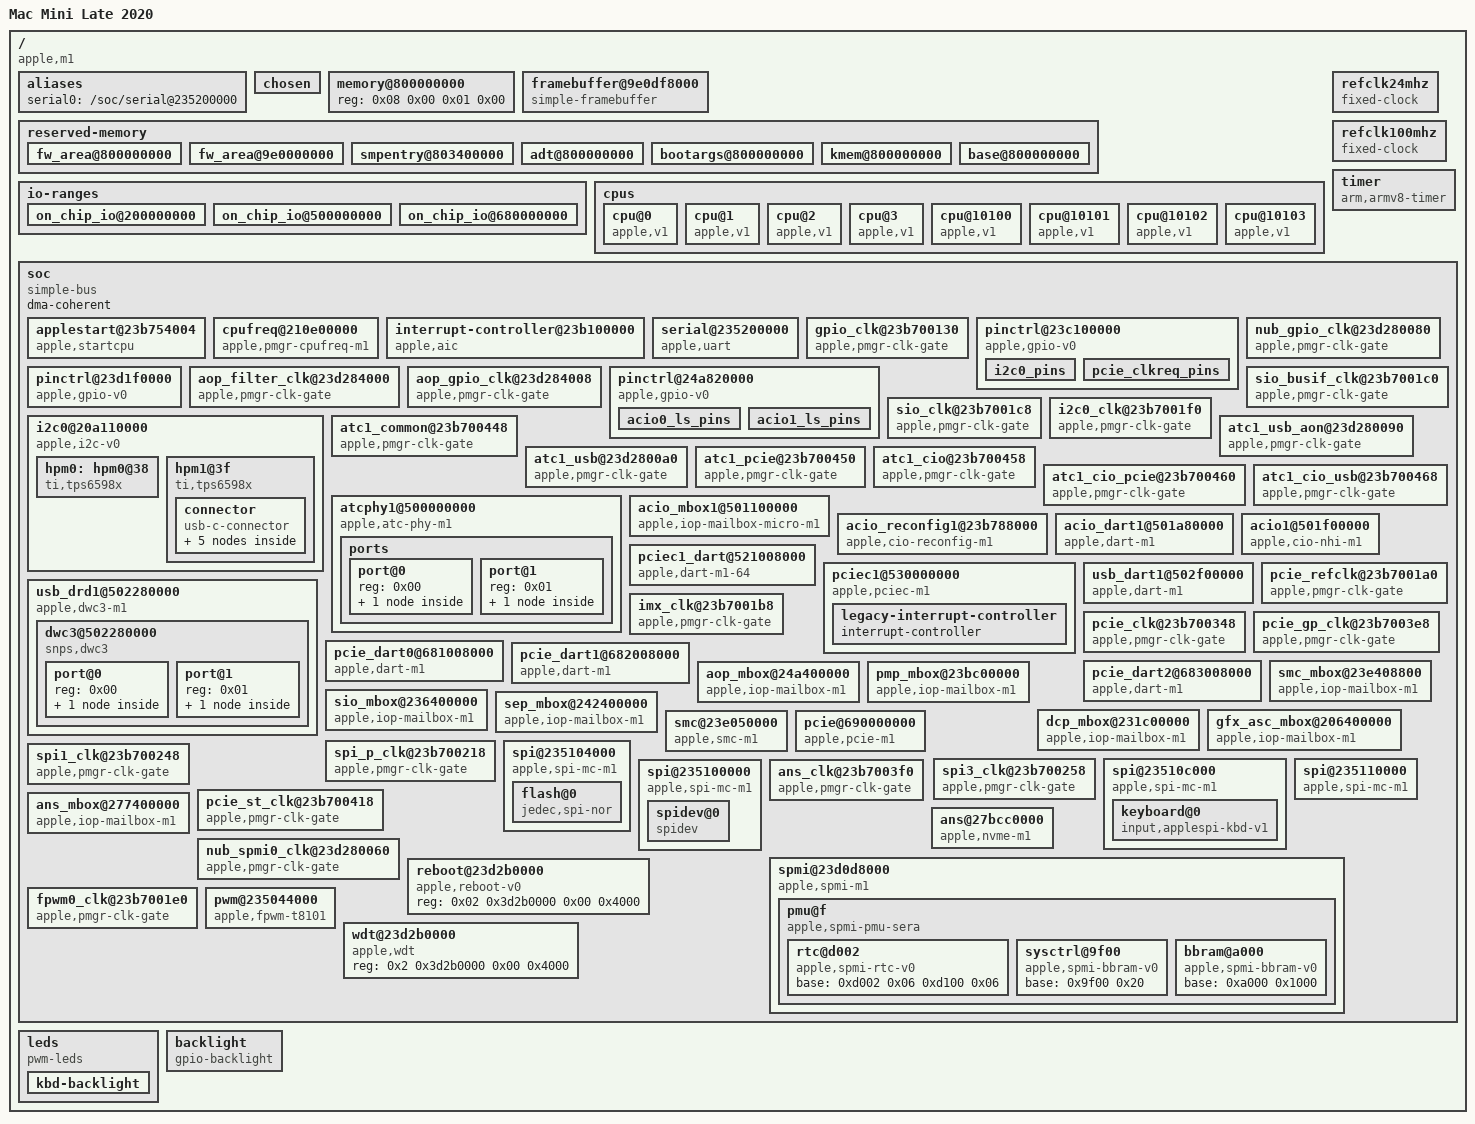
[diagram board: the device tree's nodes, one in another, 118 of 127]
/dts-v1/;

/ {
	model = "Mac Mini Late 2020";
	compatible = "apple,m1";
	hardware-model = "J274";
	interrupt-parent = <0x01>;
	#address-cells = <0x02>;
	#size-cells = <0x02>;

	aliases {
		serial0 = "/soc/serial@235200000";
	};

	chosen {
		bootargs = "earlycon=apple_uart,0x235200000 console=tty0";
	};

	memory@800000000 {
		device_type = "memory";
		reg = <0x08 0x00 0x01 0x00>;
	};

	framebuffer@9e0df8000 {
		compatible = "simple-framebuffer";
		reg = <0x0b 0xdf438000 0x00 0x3e80000>;
		format = "x8r8g8b8";
		height = <0x640>;
		stride = <0x2800>;
		width = <0xa00>;
		status = "okay";
		backlight = <0x02>;
	};

	reserved-memory {
		#address-cells = <0x02>;
		#size-cells = <0x02>;
		ranges;

		fw_area@800000000 {
			reg = <0x08 0x00 0x00 0x1f44000>;
			no-map;
		};

		fw_area@9e0000000 {
			reg = <0x0b 0xd9498000 0x00 0x26b68000>;
			no-map;
		};

		smpentry@803400000 {
			reg = <0x08 0x4df4000 0x00 0x4000>;
			no-map;
		};

		adt@800000000 {
			reg = "adtgoeshere!!!!";
			no-map;
		};

		bootargs@800000000 {
			reg = "bootargsgohere!";
			no-map;
		};

		kmem@800000000 {
			reg = "kmemgoeshere!!!";
			no-map;
		};

		base@800000000 {
			reg = "basegoeshere!!!";
			no-map;
		};
	};

	io-ranges {
		#address-cells = <0x02>;
		#size-cells = <0x02>;
		ranges;

		on_chip_io@200000000 {
			reg = <0x02 0x00 0x02 0x00>;
			type = <0x01>;
		};

		on_chip_io@500000000 {
			reg = <0x05 0x00 0x00 0x80000000>;
			type = <0x01>;
		};

		on_chip_io@680000000 {
			reg = <0x06 0x80000000 0x00 0x20000000>;
			type = <0x01>;
		};
	};

	cpus {
		#address-cells = <0x01>;
		#size-cells = <0x00>;

		cpu@0 {
			device_type = "cpu";
			compatible = "apple,v1";
			reg = <0x00>;
			enable-method = "apple,startcpu";
			apple,cluster = <0x00>;
		};

		cpu@1 {
			device_type = "cpu";
			compatible = "apple,v1";
			reg = <0x01>;
			enable-method = "apple,startcpu";
			apple,cluster = <0x00>;
		};

		cpu@2 {
			device_type = "cpu";
			compatible = "apple,v1";
			reg = <0x02>;
			enable-method = "apple,startcpu";
			apple,cluster = <0x00>;
		};

		cpu@3 {
			device_type = "cpu";
			compatible = "apple,v1";
			reg = <0x03>;
			enable-method = "apple,startcpu";
			apple,cluster = <0x00>;
		};

		cpu@10100 {
			device_type = "cpu";
			compatible = "apple,v1";
			reg = <0x10100>;
			enable-method = "apple,startcpu";
			apple,cluster = <0x01>;
		};

		cpu@10101 {
			device_type = "cpu";
			compatible = "apple,v1";
			reg = <0x10101>;
			enable-method = "apple,startcpu";
			apple,cluster = <0x01>;
		};

		cpu@10102 {
			device_type = "cpu";
			compatible = "apple,v1";
			reg = <0x10102>;
			enable-method = "apple,startcpu";
			apple,cluster = <0x01>;
		};

		cpu@10103 {
			device_type = "cpu";
			compatible = "apple,v1";
			reg = <0x10103>;
			enable-method = "apple,startcpu";
			apple,cluster = <0x01>;
		};
	};

	refclk24mhz {
		compatible = "fixed-clock";
		#clock-cells = <0x00>;
		clock-frequency = <0x16e3600>;
		clock-output-names = "refclk24mhz";
		phandle = <0x03>;
	};

	refclk100mhz {
		compatible = "fixed-clock";
		#clock-cells = <0x00>;
		clock-frequency = <0x5f5e100>;
		clock-output-names = "refclk100mhz";
		phandle = <0x17>;
	};

	timer {
		compatible = "arm,armv8-timer";
		interrupts = <1 1 4 1 0 4>;
		clock-frequency = <0x16e3600>;
	};

	soc {
		compatible = "simple-bus";
		#address-cells = <0x02>;
		#size-cells = <0x02>;
		ranges;
		dma-coherent;

		applestart@23b754004 {
			compatible = "apple,startcpu";
			reg = <0x02 0x3b754004 0x00 0x0c 0x02 0x10050000 0x00 0x08 0x02 0x10030fb0 0x00 0x04 0x02 0x3b754004 0x00 0x0c 0x02 0x10150000 0x00 0x08 0x02 0x10130fb0 0x00 0x04 0x02 0x3b754004 0x00 0x0c 0x02 0x10250000 0x00 0x08 0x02 0x10230fb0 0x00 0x04 0x02 0x3b754004 0x00 0x0c 0x02 0x10350000 0x00 0x08 0x02 0x10330fb0 0x00 0x04 0x02 0x3b754004 0x00 0x0c 0x02 0x11050000 0x00 0x08 0x02 0x11030fb0 0x00 0x04 0x02 0x3b754004 0x00 0x0c 0x02 0x11150000 0x00 0x08 0x02 0x11130fb0 0x00 0x04 0x02 0x3b754004 0x00 0x0c 0x02 0x11250000 0x00 0x08 0x02 0x11230fb0 0x00 0x04 0x02 0x3b754004 0x00 0x0c 0x02 0x11350000 0x00 0x08 0x02 0x11330fb0 0x00 0x04>;
		};

		cpufreq@210e00000 {
			compatible = "apple,pmgr-cpufreq-m1";
			reg = <0x02 0x10e00000 0x00 0x100000 0x02 0x11e00000 0x00 0x100000 0x02 0x3b700000 0x00 0x100000 0x02 0x200000 0x00 0x200000>;
			tunable-ecpu-states = <0x1aaaa 0x22c 0x1075f 0x26d 0xc031 0x2a6 0x963c 0x300 0x7c07 0x35b>;
			tunable-pcpu-states = <0x1aaaa 0x254 0x1352d 0x27d 0xf26c 0x2a3 0xc760 0x2a9 0xaaaa 0x2d1 0x9425 0x2e4 0x82e1 0x310 0x7537 0x320 0x6b33 0x342 0x62c3 0x377 0x5c5a 0x3a0 0x55ad 0x3d2 0x52af 0x3d2 0x516c 0x3d2 0x4fe6 0x3d2>;
			tunable-pcpu-fast-freq = <0x888>;
			tunable-pcpu-fast-dcfg = <0x133 0x55555340>;
		};

		interrupt-controller@23b100000 {
			compatible = "apple,aic";
			#interrupt-cells = <0x03>;
			interrupt-controller;
			reg = <0x02 0x3b100000 0x00 0x8000>;
			fast-ipi;
			phandle = <0x01>;
		};

		serial@235200000 {
			compatible = "apple,uart";
			reg = <0x02 0x35200000 0x00 0x4000>;
			interrupts = <0x00 0x25d 0x04>;
			clocks = <0x03>;
			clock-names = "refclk";
			index = <0x00>;
		};

		gpio_clk@23b700130 {
			compatible = "apple,pmgr-clk-gate";
			#clock-cells = <0x00>;
			reg = <0x02 0x3b700130 0x00 0x08>;
			clocks = <0x03>;
			clock-output-names = "gpio_clk";
			phandle = <0x04>;
		};

		pinctrl@23c100000 {
			compatible = "apple,gpio-v0";
			reg = <0x02 0x3c100000 0x00 0x100000>;
			pin-count = <0xd4>;
			interrupts = <0x00 0xbe 0x04 0x00 0xbf 0x04 0x00 0xc0 0x04 0x00 0xc1 0x04 0x00 0xc2 0x04 0x00 0xc3 0x04 0x00 0xc4 0x04>;
			clocks = <0x04>;
			gpio-controller;
			#gpio-cells = <0x02>;
			interrupt-controller;
			#interrupt-cells = <0x02>;
			phandle = <0x0c>;

			i2c0_pins {
				pins = "gpio192\0gpio188";
				function = "periph";
				phandle = <0x0b>;
			};

			pcie_clkreq_pins {
				pins = "gpio150\0gpio151\0gpio32";
				function = "periph";
				phandle = <0x36>;
			};
		};

		nub_gpio_clk@23d280080 {
			compatible = "apple,pmgr-clk-gate";
			#clock-cells = <0x00>;
			reg = <0x02 0x3d280080 0x00 0x08>;
			clocks = <0x03>;
			clock-output-names = "nub_gpio_clk";
			phandle = <0x05>;
		};

		pinctrl@23d1f0000 {
			compatible = "apple,gpio-v0";
			reg = <0x02 0x3d1f0000 0x00 0x4000>;
			pin-count = <0x17>;
			pin-base = <0xd4>;
			pin-prefix = "nubgpio";
			interrupts = <0x00 0x14a 0x04 0x00 0x14b 0x04 0x00 0x14c 0x04 0x00 0x14d 0x04 0x00 0x14e 0x04 0x00 0x14f 0x04 0x00 0x150 0x04>;
			clocks = <0x05>;
			gpio-controller;
			#gpio-cells = <0x02>;
			interrupt-controller;
			#interrupt-cells = <0x02>;
			phandle = <0x3f>;
		};

		aop_filter_clk@23d284000 {
			compatible = "apple,pmgr-clk-gate";
			#clock-cells = <0x00>;
			reg = <0x02 0x3d284000 0x00 0x08>;
			clocks = <0x03>;
			clock-output-names = "aop_filter_clk";
			phandle = <0x06>;
		};

		aop_gpio_clk@23d284008 {
			compatible = "apple,pmgr-clk-gate";
			#clock-cells = <0x00>;
			reg = <0x02 0x3d284008 0x00 0x08>;
			clocks = <0x06>;
			clock-output-names = "aop_gpio_clk";
			phandle = <0x07>;
		};

		pinctrl@24a820000 {
			compatible = "apple,gpio-v0";
			reg = <0x02 0x4a820000 0x00 0x4000>;
			pin-count = <0x2a>;
			pin-base = <0xeb>;
			pin-prefix = "aopgpio";
			interrupts = <0x00 0x10c 0x04 0x00 0x10d 0x04 0x00 0x10e 0x04 0x00 0x10f 0x04 0x00 0x110 0x04 0x00 0x111 0x04 0x00 0x112 0x04>;
			clocks = <0x07>;
			gpio-controller;
			#gpio-cells = <0x02>;
			interrupt-controller;
			#interrupt-cells = <0x02>;

			acio0_ls_pins {
				pins = "aopgpio39";
				function = "periph";
			};

			acio1_ls_pins {
				pins = "aopgpio41";
				function = "periph";
				phandle = <0x28>;
			};
		};

		sio_busif_clk@23b7001c0 {
			compatible = "apple,pmgr-clk-gate";
			#clock-cells = <0x00>;
			reg = <0x02 0x3b7001c0 0x00 0x08>;
			clocks = <0x03>;
			clock-output-names = "sio_busif_clk";
			phandle = <0x08>;
		};

		sio_clk@23b7001c8 {
			compatible = "apple,pmgr-clk-gate";
			#clock-cells = <0x00>;
			reg = <0x02 0x3b7001c8 0x00 0x08>;
			clocks = <0x08>;
			clock-output-names = "sio_clk";
			phandle = <0x09>;
		};

		i2c0_clk@23b7001f0 {
			compatible = "apple,pmgr-clk-gate";
			#clock-cells = <0x00>;
			reg = <0x02 0x3b7001f0 0x00 0x08>;
			clocks = <0x09>;
			clock-output-names = "i2c0_clk";
			phandle = <0x0a>;
		};

		i2c0@20a110000 {
			compatible = "apple,i2c-v0";
			reg = <0x02 0x35010000 0x00 0x4000>;
			interrupts = <0x00 0x273 0x04>;
			clocks = <0x0a>;
			pinctrl-0 = <0x0b>;
			pinctrl-names = "default";
			#address-cells = <0x01>;
			#size-cells = <0x00>;

            hpm0: hpm0@38 {
                compatible = "ti,tps6598x";
                reg = <0x38>;
                interrupt-parent = <0x0c>;
                interrupts = <106 8>;

                no-long-writes;
		just-init;
            };

			hpm1@3f {
				compatible = "ti,tps6598x";
				reg = <0x3f>;
				interrupt-parent = <0x0c>;
				interrupts = <0x6a 0x08>;
				no-long-writes;

				connector {
					compatible = "usb-c-connector";
					label = "USB-C B";
					power-role = "source";
					data-role = "host";

					ports {
						#address-cells = <0x01>;
						#size-cells = <0x00>;

						port@0 {
							reg = <0x00>;

							endpoint {
								remote-endpoint = <0x0d>;
								phandle = <0x2e>;
							};
						};

						port@1 {
							reg = <0x01>;

							endpoint {
								remote-endpoint = <0x0e>;
								phandle = <0x20>;
							};
						};
					};
				};
			};
		};

		atc1_common@23b700448 {
			compatible = "apple,pmgr-clk-gate";
			#clock-cells = <0x00>;
			reg = <0x02 0x3b700448 0x00 0x08>;
			clocks = <0x03>;
			clock-output-names = "atc1_common";
			phandle = <0x1c>;
		};

		atc1_usb_aon@23d280090 {
			compatible = "apple,pmgr-clk-gate";
			#clock-cells = <0x00>;
			reg = <0x02 0x3d280090 0x00 0x08>;
			clocks = <0x1c>;
			clock-output-names = "atc1_usb_aon";
			phandle = <0x1d>;
		};

		atc1_usb@23d2800a0 {
			compatible = "apple,pmgr-clk-gate";
			#clock-cells = <0x00>;
			reg = <0x02 0x3d2800a0 0x00 0x08>;
			clocks = <0x1d>;
			clock-output-names = "atc1_usb";
			phandle = <0x1f>;
		};

		atc1_pcie@23b700450 {
			compatible = "apple,pmgr-clk-gate";
			#clock-cells = <0x00>;
			reg = <0x02 0x3b700450 0x00 0x08>;
			clocks = <0x1c>;
			clock-output-names = "atc1_pcie";
			phandle = <0x2a>;
		};

		atc1_cio@23b700458 {
			compatible = "apple,pmgr-clk-gate";
			#clock-cells = <0x00>;
			reg = <0x02 0x3b700458 0x00 0x08>;
			clocks = <0x1c>;
			clock-output-names = "atc1_cio";
			phandle = <0x1e>;
		};

		atc1_cio_pcie@23b700460 {
			compatible = "apple,pmgr-clk-gate";
			#clock-cells = <0x00>;
			reg = <0x02 0x3b700460 0x00 0x08>;
			clocks = <0x1e>;
			clock-output-names = "atc1_cio_pcie";
			phandle = <0x22>;
		};

		atc1_cio_usb@23b700468 {
			compatible = "apple,pmgr-clk-gate";
			#clock-cells = <0x00>;
			reg = <0x02 0x3b700468 0x00 0x08>;
			clocks = <0x1e>;
			clock-output-names = "atc1_cio_usb";
			phandle = <0x23>;
		};

		atcphy1@500000000 {
			compatible = "apple,atc-phy-m1";
			clocks = <0x1f>;
			reg = <0x05 0x00 0x00 0x1000000 0x05 0x2000000 0x00 0x1080000>;
			#phy-cells = <0x00>;
			usb-role-switch;
			orientation-switch;
			mode-switch;
			accessory;
			#clock-cells = <0x00>;
			clock-output-names = "utmi1clk";
			phandle = <0x27>;
			tunable-ATC0AXI2AF = <0x00 0x03 0x00 0x30 0xffffffff 0xffff 0x34 0xffffffff 0xffff 0x400 0x400103ff 0x40010001 0x600 0x1ffffff 0x1ffffff 0x738 0x1ff01ff 0x400040 0x798 0x1ff01ff 0x600020 0x800 0x100 0x100 0x900 0x03 0x00 0x920 0x03 0x00>;
			tunable-ATC_FABRIC = <0x11045004 0x3f003f 0x200020 0x1104500c 0xf1 0xa1 0x11045010 0x801f 0x04 0x11045018 0x3f003f 0x200020 0x11045020 0xf1 0xa1 0x11045024 0x801f 0x04 0x1104502c 0x7f007f 0x520052 0x11045034 0xf1 0x71 0x11045038 0x01 0x01 0x1104503c 0x01 0x01 0x11045040 0x801f 0x04 0x11045048 0x1f 0x10 0x11045050 0x801f 0x04 0x11045058 0x7f007f 0x450045 0x11045060 0xf1 0x51 0x11045064 0x801f 0x04 0x1104506c 0x3f 0x20 0x11045074 0x801f 0x04 0x1104507c 0x01 0x01 0x11045080 0x801f 0x04 0x11045088 0x1f001f 0x100010 0x11045090 0x01 0x01 0x11045094 0x01 0x01 0x11045098 0x801f 0x04 0x110450a0 0xff00ff 0xc000c0 0x110450a4 0x801f 0x04 0x110450ac 0x3f 0x20 0x110450b4 0x801f 0x04 0x110450bc 0x3f 0x20 0x110450c4 0x801f 0x04 0x110450cc 0x1f001f 0x100010 0x110450d4 0x01 0x01 0x110450d8 0x01 0x01 0x110450dc 0x801f 0x04 0x110450e4 0x01 0x01 0x110450e8 0x01 0x01 0x110450ec 0x801f 0x04 0x110450f4 0xffffffff 0x1010101 0x110450f8 0xffff 0x101 0x110450fc 0xffffffff 0x1010101 0x11045100 0xffff 0x101 0x11045104 0x801f 0x04 0x1104510c 0x01 0x01 0x11045110 0x01 0x01 0x11045114 0x801f 0x04 0x1104511c 0x01 0x01 0x11045120 0x01 0x01 0x11045124 0x801f 0x04 0x1104512c 0x01 0x01 0x11045130 0x01 0x01 0x11045134 0x801f 0x04 0x1104513c 0x01 0x01 0x11045140 0x801f 0x04 0x11045148 0x01 0x01 0x1104514c 0x01 0x01 0x11045150 0x801f 0x04 0x11045158 0x801f 0x04 0x11045160 0xffffffff 0x1010101 0x11045164 0xffffffff 0x1010101 0x11045168 0xffff 0x101 0x1104516c 0x801f 0x04 0x11045174 0x01 0x01 0x11045178 0x01 0x01 0x1104517c 0x801f 0x04 0x11045184 0x01 0x01 0x11045188 0x801f 0x04 0x1104508c 0xf1 0x11>;
			tunable-AUS_CMN_SHM = <0x11000a00 0x3fc00 0x3c000>;
			tunable-AUS_CMN_TOP = <0x11000808 0xfff0ff0 0x2220220>;
			tunable-AUSPLL_CORE = <0x1100222c 0x900 0x900 0x11002278 0x8000000 0x00 0x110022a4 0x01 0x01>;
			tunable-AUSPLL_TOP = <0x11002088 0xf0000 0x60000 0x11002094 0xf0000 0x60000 0x110020a0 0xf0000 0x50000 0x110020ac 0xf0000 0x50000 0x110020b8 0xf0000 0x50000>;
			tunable-CIO3PLL_CORE = <0x11002a00 0x22 0x22 0x11002a1c 0x7000 0x2000 0x11002a20 0x20007 0x20003 0x11002a28 0x10 0x10 0x11002a9c 0x20000 0x00>;
			tunable-CIO3PLL_TOP = <0x11002810 0xffffffff 0xa0a0a04 0x11002888 0x1ff 0x127 0x11002894 0x1ff 0x115>;
			tunable-CIO_LN0_AUSPMA_RX_EQ = <0x1100a048 0x0f 0x02 0x1100a050 0xfff 0xfff 0x1100a054 0x0f 0x02 0x1100a05c 0xfff 0xfff 0x1100a07c 0xfff 0x7ff 0x1100a098 0x3f 0x3f 0x1100a0bc 0x7fc00000 0x3000000 0x1100a048 0x0f 0x02 0x1100a050 0xfff 0xfff 0x1100a054 0x0f 0x02 0x1100a05c 0xfff 0xfff 0x1100a07c 0xfff 0x7ff 0x1100a098 0x3f 0x3f 0x1100a0bc 0x7fc00000 0x3000000>;
			tunable-USB_LN0_AUSPMA_RX_EQ;
			tunable-CIO_LN0_AUSPMA_RX_SHM = <0x1100b01c 0x7fc0fff 0x1c00c21 0x1100b024 0xc000 0xc000 0x1100b028 0x600 0x600 0x1100b02c 0x70 0x50 0x1100b038 0x1f800000 0x13000000 0x1100b03c 0x7000000 0x7000000 0x1100b05c 0x400 0x400 0x1100b084 0x7c1f 0x6815 0x1100b08c 0x1c0000 0x100000 0x1100b01c 0x7fc0fff 0x1c00c21 0x1100b024 0xc000 0xc000 0x1100b028 0x600 0x600 0x1100b02c 0x70 0x50 0x1100b038 0x1f800000 0x13000000 0x1100b03c 0x7000000 0x7000000 0x1100b05c 0x400 0x400 0x1100b084 0xf83e0 0xd02a0 0x1100b08c 0x1c0000 0x100000>;
			tunable-USB_LN0_AUSPMA_RX_SHM = <0x1100b01c 0x7fc0fff 0x1c00c21 0x1100b024 0xc000 0xc000 0x1100b028 0x600 0x600 0x1100b02c 0x70 0x50 0x1100b038 0x1f800008 0x13000008 0x1100b03c 0x7000000 0x7000000 0x1100b080 0xffffffff 0x808550 0x1100b084 0x3f07c1f 0x200701c 0x1100b088 0x3f03f03f 0x20020020 0x1100b08c 0xfc0 0x800 0x1100b01c 0x7fc0fff 0x1c00c21 0x1100b024 0xc000 0xc000 0x1100b028 0x600 0x600 0x1100b02c 0x70 0x50 0x1100b038 0x1f800008 0x13000008 0x1100b03c 0x7000000 0x7000000 0x1100b080 0xffffffff 0x808550 0x1100b084 0x3ff83e0 0x20e0380 0x1100b088 0x3f03f03f 0x20020020 0x1100b08c 0xfc0 0x800>;
			tunable-CIO_LN0_AUSPMA_RX_TOP = <0x11009000 0x7e000000 0x1e000000 0x11009014 0x8000 0x00 0x1100902c 0x4ff6ff3f 0x4aa0ff3f 0x11009030 0x11fff00c 0x11000004 0x11009040 0x30000 0x00 0x11009068 0x38 0x18 0x11009074 0x3f 0x3e 0x11009084 0x1fff0e 0x400a 0x11009088 0x3fff 0x1224 0x110090ac 0x1f8000 0x40000 0x110090ec 0xfffffffc 0x80000 0x11009104 0xffff 0x202 0x11009108 0x03 0x00 0x11009110 0xffffff0 0x2222220 0x11009118 0x02 0x00 0x11009000 0x7e000000 0x1e000000 0x11009014 0x8000 0x00 0x1100902c 0x4ff6ff3f 0x4aa0ff3f 0x11009030 0x11fff00c 0x11000004 0x11009040 0x30000 0x00 0x11009068 0x38 0x18 0x11009074 0x3f 0x3e 0x11009084 0x1fff0e 0x400a 0x11009088 0x3fff 0x1224 0x110090ac 0x1f8000 0x40000 0x110090e4 0xfffffff 0x1a50694 0x110090ec 0xfffffffc 0x80000 0x11009104 0xffff 0x202 0x11009108 0x03 0x00 0x11009110 0xffffff0 0x2222220 0x11009118 0x02 0x00>;
			tunable-USB_LN0_AUSPMA_RX_TOP = <0x11009000 0x7e000000 0x3e000000 0x11009014 0x8000 0x00 0x1100902c 0x20f00f0f 0x20a00f0f 0x11009030 0xff3100 0xff0000 0x11009040 0x30000 0x00 0x11009044 0x30000 0x30000 0x11009068 0x38 0x18 0x11009074 0x3f 0x3e 0x11009084 0x1fff0e 0x400a 0x11009088 0x3fff 0x1224 0x110090ac 0x1f8000 0x40000 0x110090dc 0xffffffff 0xcc28c48a 0x110090ec 0xfffffffc 0x2604 0x110090f4 0xffffffff 0x3280650 0x110090fc 0x7c1f 0x1004 0x11009104 0xffff 0x202 0x11009108 0x03 0x00 0x11009110 0xffffff0 0x2222220 0x11009000 0x7e000000 0x3e000000 0x11009014 0x8000 0x00 0x1100902c 0x20f00f0f 0x20a00f0f 0x11009030 0xff3100 0x00 0x11009040 0x30000 0x00 0x11009044 0x30000 0x30000 0x11009068 0x38 0x18 0x11009074 0x3f 0x3e 0x11009084 0x1fff0e 0x400a 0x11009088 0x3fff 0x1224 0x110090ac 0x1f8000 0x40000 0x110090dc 0xffffffff 0xcc28c48a 0x110090ec 0xfffffffc 0x2604 0x110090f4 0xffffffff 0x3280650 0x110090fc 0x7c1f 0x1004 0x11009104 0xffff 0x202 0x11009108 0x03 0x00 0x11009110 0xffffff0 0x2222220>;
			tunable-CIO_LN0_AUSPMA_TX_TOP = <0x1100c008 0xfc00 0x6c00 0x1100c030 0x3fc0 0x2a00 0x1100c080 0xf80000 0x180000 0x1100c08c 0xffffff0 0x2222220 0x1100c008 0xfc00 0x6c00 0x1100c030 0x3fc0 0x2a00 0x1100c080 0xf80000 0x180000 0x1100c08c 0xffffff0 0x2222220>;
			tunable-DP_LN0_AUSPMA_TX_TOP = <0x1100c008 0xfc00 0x6c00 0x1100c030 0x3fc0 0x2a00 0x1100c08c 0xffffff0 0x2222220 0x1100c080 0xf80000 0x180000>;
			tunable-USB_LN0_AUSPMA_TX_TOP = <0x1100c008 0xfc00 0x6c00 0x1100c018 0x1fffffc0 0x3018180 0x1100c01c 0x7ff 0x5a0 0x1100c030 0x3fc0 0x2a00 0x1100c080 0xf80000 0x180000 0x1100c08c 0xffffff0 0x2222220 0x1100c008 0xfc00 0x6c00 0x1100c018 0x1fffffc0 0x3018180 0x1100c01c 0x7ff 0x5a0 0x1100c030 0x3fc0 0x2a00 0x1100c080 0xf80000 0x180000 0x1100c08c 0xffffff0 0x2222220>;
			tunable-CIO_LN1_AUSPMA_RX_EQ = <0x11011048 0x0f 0x02 0x11011050 0xfff 0xfff 0x11011054 0x0f 0x02 0x1101105c 0xfff 0xfff 0x1101107c 0xfff 0x7ff 0x11011098 0x3f 0x3f 0x110110bc 0x7fc00000 0x3000000 0x11011048 0x0f 0x02 0x11011050 0xfff 0xfff 0x11011054 0x0f 0x02 0x1101105c 0xfff 0xfff 0x1101107c 0xfff 0x7ff 0x11011098 0x3f 0x3f 0x110110bc 0x7fc00000 0x3000000>;
			tunable-USB_LN1_AUSPMA_RX_EQ;
			tunable-CIO_LN1_AUSPMA_RX_SHM = <0x1101201c 0x7fc0fff 0x1c00c21 0x11012024 0xc000 0xc000 0x11012028 0x600 0x600 0x1101202c 0x70 0x50 0x11012038 0x1f800000 0x13000000 0x1101203c 0x7000000 0x7000000 0x1101205c 0x400 0x400 0x11012084 0x7c1f 0x6815 0x1101208c 0x1c0000 0x100000 0x1101201c 0x7fc0fff 0x1c00c21 0x11012024 0xc000 0xc000 0x11012028 0x600 0x600 0x1101202c 0x70 0x50 0x11012038 0x1f800000 0x13000000 0x1101203c 0x7000000 0x7000000 0x1101205c 0x400 0x400 0x11012084 0xf83e0 0xd02a0 0x1101208c 0x1c0000 0x100000>;
			tunable-USB_LN1_AUSPMA_RX_SHM = <0x1101201c 0x7fc0fff 0x1c00c21 0x11012024 0xc000 0xc000 0x11012028 0x600 0x600 0x1101202c 0x70 0x50 0x11012038 0x1f800008 0x13000008 0x1101203c 0x7000000 0x7000000 0x11012080 0xffffffff 0x808550 0x11012084 0x3f07c1f 0x200701c 0x11012088 0x3f03f03f 0x20020020 0x1101208c 0xfc0 0x800 0x1101201c 0x7fc0fff 0x1c00c21 0x11012024 0xc000 0xc000 0x11012028 0x600 0x600 0x1101202c 0x70 0x50 0x11012038 0x1f800008 0x13000008 0x1101203c 0x7000000 0x7000000 0x11012080 0xffffffff 0x808550 0x11012084 0x3ff83e0 0x20e0380 0x11012088 0x3f03f03f 0x20020020 0x1101208c 0xfc0 0x800>;
			tunable-CIO_LN1_AUSPMA_RX_TOP = <0x11010000 0x7e000000 0x1e000000 0x11010014 0x8000 0x00 0x1101002c 0x4ff6ff3f 0x4aa0ff3f 0x11010030 0x11fff00c 0x11000004 0x11010040 0x30000 0x00 0x11010068 0x38 0x18 0x11010074 0x3f 0x3e 0x11010084 0x1fff0e 0x400a 0x11010088 0x3fff 0x1224 0x110100ac 0x1f8000 0x40000 0x110100ec 0xfffffffc 0x80000 0x11010104 0xffff 0x202 0x11010108 0x03 0x00 0x11010110 0xffffff0 0x2222220 0x11010118 0x02 0x00 0x11010000 0x7e000000 0x1e000000 0x11010014 0x8000 0x00 0x1101002c 0x4ff6ff3f 0x4aa0ff3f 0x11010030 0x11fff00c 0x11000004 0x11010040 0x30000 0x00 0x11010068 0x38 0x18 0x11010074 0x3f 0x3e 0x11010084 0x1fff0e 0x400a 0x11010088 0x3fff 0x1224 0x110100ac 0x1f8000 0x40000 0x110100e4 0xfffffff 0x1a50694 0x110100ec 0xfffffffc 0x80000 0x11010104 0xffff 0x202 0x11010108 0x03 0x00 0x11010110 0xffffff0 0x2222220 0x11010118 0x02 0x00>;
			tunable-USB_LN1_AUSPMA_RX_TOP = <0x11010000 0x7e000000 0x3e000000 0x11010014 0x8000 0x00 0x1101002c 0x20f00f0f 0x20a00f0f 0x11010030 0xff3100 0xff0000 0x11010040 0x30000 0x00 0x11010044 0x30000 0x30000 0x11010068 0x38 0x18 0x11010074 0x3f 0x3e 0x11010084 0x1fff0e 0x400a 0x11010088 0x3fff 0x1224 0x110100ac 0x1f8000 0x40000 0x110100dc 0xffffffff 0xcc28c48a 0x110100ec 0xfffffffc 0x2604 0x110100f4 0xffffffff 0x3280650 0x110100fc 0x7c1f 0x1004 0x11010104 0xffff 0x202 0x11010108 0x03 0x00 0x11010110 0xffffff0 0x2222220 0x11010000 0x7e000000 0x3e000000 0x11010014 0x8000 0x00 0x1101002c 0x20f00f0f 0x20a00f0f 0x11010030 0xff3100 0x00 0x11010040 0x30000 0x00 0x11010044 0x30000 0x30000 0x11010068 0x38 0x18 0x11010074 0x3f 0x3e 0x11010084 0x1fff0e 0x400a 0x11010088 0x3fff 0x1224 0x110100ac 0x1f8000 0x40000 0x110100dc 0xffffffff 0xcc28c48a 0x110100ec 0xfffffffc 0x2604 0x110100f4 0xffffffff 0x3280650 0x110100fc 0x7c1f 0x1004 0x11010104 0xffff 0x202 0x11010108 0x03 0x00 0x11010110 0xffffff0 0x2222220>;
			tunable-CIO_LN1_AUSPMA_TX_TOP = <0x11013008 0xfc00 0x6c00 0x11013030 0x3fc0 0x2a00 0x11013080 0xf80000 0x180000 0x1101308c 0xffffff0 0x2222220 0x11013008 0xfc00 0x6c00 0x11013030 0x3fc0 0x2a00 0x11013080 0xf80000 0x180000 0x1101308c 0xffffff0 0x2222220>;
			tunable-DP_LN1_AUSPMA_TX_TOP = <0x11013008 0xfc00 0x6c00 0x11013030 0x3fc0 0x2a00 0x1101308c 0xffffff0 0x2222220 0x11013080 0xf80000 0x180000>;
			tunable-USB_LN1_AUSPMA_TX_TOP = <0x11013008 0xfc00 0x6c00 0x11013018 0x1fffffc0 0x3018180 0x1101301c 0x7ff 0x5a0 0x11013030 0x3fc0 0x2a00 0x11013080 0xf80000 0x180000 0x1101308c 0xffffff0 0x2222220 0x11013008 0xfc00 0x6c00 0x11013018 0x1fffffc0 0x3018180 0x1101301c 0x7ff 0x5a0 0x11013030 0x3fc0 0x2a00 0x11013080 0xf80000 0x180000 0x1101308c 0xffffff0 0x2222220>;
			tunable-USB_ACIOPHY_TOP = <0x11000118 0xffffffff 0x8446abe6 0x1100011c 0xffffffff 0x18080887 0x11000124 0xffffffff 0x640a 0x11000118 0xffffffff 0x8446abe6 0x1100011c 0xffffffff 0x18080887 0x11000124 0xffffffff 0x640a>;
			tunable-fuse = <0x11002a38 0x7f 0x26 0x11002a38 0xfe0000 0x580000 0x11002aa4 0x60000 0x20000 0x11000a04 0x7c 0x34 0x11002aa4 0x60000 0x00 0x11002a20 0x1c000 0x14000 0x1100222c 0x600 0x00 0x1100222c 0x7000 0x2000 0x110022a4 0x60000 0x40000 0x11002220 0x1c000 0x8000 0x11000a04 0x7c 0x34>;

			ports {
				#address-cells = <0x01>;
				#size-cells = <0x00>;

				port@0 {
					reg = <0x00>;

					endpoint {
						phandle = <0x0e>;
					};
				};

				port@1 {
					reg = <0x01>;

					endpoint {
						phandle = <0x2f>;
					};
				};
			};
		};

		acio_mbox1@501100000 {
			compatible = "apple,iop-mailbox-micro-m1";
			reg = <0x05 0x1100000 0x00 0x4000>;
			interrupts = <0x00 0x37c 0x04 0x00 0x37f 0x04>;
			#mbox-cells = <0x01>;
			endpoints = <0x20>;
			wait-init;
			phandle = <0x24>;
		};

		acio_reconfig1@23b788000 {
			compatible = "apple,cio-reconfig-m1";
			clocks = <0x1e 0x22 0x23>;
			reg = <0x02 0x3b788000 0x00 0x4000>;
			mboxes = <0x24 0x20>;
			#clock-cells = <0x00>;
			clock-output-names = "acio1clk";
			phandle = <0x25>;
		};

		acio_dart1@501a80000 {
			compatible = "apple,dart-m1";
			clocks = <0x25>;
			reg = <0x05 0x1a80000 0x00 0x4000>;
			interrupts = <0x00 0x37a 0x04>;
			page-bits = <0x0e>;
			sid-mask = <0x8003>;
			sid-bypass-mask = <0x8000>;
			#iommu-cells = <0x01>;
			phandle = <0x26>;
		};

		acio1@501f00000 {
			compatible = "apple,cio-nhi-m1";
			clocks = <0x25>;
			reg = <0x05 0x1f00000 0x00 0x100000 0x05 0x1ac0000 0x00 0x440000>;
			interrupts = <0x00 0x35f 0x01 0x00 0x360 0x01 0x00 0x361 0x01 0x00 0x362 0x01 0x00 0x363 0x01 0x00 0x364 0x01 0x00 0x365 0x01 0x00 0x366 0x01 0x00 0x367 0x01 0x00 0x368 0x01 0x00 0x369 0x01 0x00 0x36a 0x01 0x00 0x36b 0x01 0x00 0x36c 0x01 0x00 0x36d 0x01 0x00 0x36e 0x01 0x00 0x36f 0x01 0x00 0x370 0x01 0x00 0x371 0x01 0x00 0x372 0x01 0x00 0x373 0x01 0x00 0x374 0x01 0x00 0x375 0x01 0x00 0x376 0x01>;
			iommus = <0x26 0x01>;
			phys = <0x27>;
			pinctrl-0 = <0x28>;
			pinctrl-names = "default";
			num-rings = <0x0c>;
			pcie = <0x29>;
			tunable-fw_int_ctl_management = <0x4000 0x1000000f 0x10000002 0x4004 0x1000000f 0x10000002 0x4008 0x1000000f 0x10000002 0x400c 0x1000000f 0x10000002 0x4010 0x1000000f 0x10000002 0x4014 0x1000000f 0x10000002 0x4018 0x1000000f 0x10000002 0x401c 0x1000000f 0x10000002 0x4020 0x1000000f 0x10000002 0x4024 0x1000000f 0x10000002 0x4028 0x1000000f 0x10000002 0x402c 0x1000000f 0x10000002 0x4040 0x1000000f 0x03 0x4044 0x1000000f 0x03 0x4048 0x1000000f 0x03 0x404c 0x1000000f 0x03 0x4050 0x1000000f 0x03 0x4054 0x1000000f 0x03 0x4058 0x1000000f 0x03 0x405c 0x1000000f 0x03 0x4060 0x1000000f 0x03 0x4064 0x1000000f 0x03 0x4068 0x1000000f 0x03 0x406c 0x1000000f 0x03 0x4080 0x1000000f 0x10000002 0x4084 0x1000000f 0x10000002 0x4088 0x1000000f 0x10000002 0x408c 0x1000000f 0x10000002 0x4090 0x1000000f 0x10000002 0x4094 0x1000000f 0x10000002 0x4098 0x1000000f 0x10000002 0x409c 0x1000000f 0x10000002 0x40a0 0x1000000f 0x10000002 0x40a4 0x1000000f 0x10000002 0x40a8 0x1000000f 0x10000002 0x40ac 0x1000000f 0x10000002 0x40c0 0x1000000f 0x10000002 0x40c4 0x1000000f 0x10000002 0x40c8 0x1000000f 0x10000002 0x40cc 0x1000000f 0x10000002 0x40d0 0x1000000f 0x10000002 0x40d4 0x1000000f 0x10000002 0x40d8 0x1000000f 0x10000002 0x40dc 0x1000000f 0x10000002 0x40e0 0x1000000f 0x10000002 0x40e4 0x1000000f 0x10000002 0x40e8 0x1000000f 0x10000002 0x40ec 0x1000000f 0x10000002 0x4100 0x1000000f 0x03 0x4104 0x1000000f 0x03 0x4108 0x1000000f 0x03 0x410c 0x1000000f 0x03 0x4110 0x1000000f 0x03 0x4114 0x1000000f 0x03 0x4118 0x1000000f 0x03 0x411c 0x1000000f 0x03 0x4120 0x1000000f 0x03 0x4124 0x1000000f 0x03 0x4128 0x1000000f 0x03 0x412c 0x1000000f 0x03 0x4140 0x1000000f 0x10000003 0x4144 0x1000000f 0x10000003 0x4148 0x1000000f 0x10000003 0x414c 0x1000000f 0x10000003 0x4150 0x1000000f 0x10000003 0x4154 0x1000000f 0x10000003 0x4158 0x1000000f 0x10000003 0x415c 0x1000000f 0x10000003 0x4160 0x1000000f 0x10000003 0x4164 0x1000000f 0x10000003 0x4168 0x1000000f 0x10000003 0x416c 0x1000000f 0x10000003 0x43f0 0x1ffffff 0x00>;
			tunable-hbw_fabric = <0x10004004 0x7f007f 0x400040 0x10004008 0x801f 0x04 0x10004010 0x7f 0x40 0x10004014 0x801f 0x04 0x1000401c 0x1f 0x10 0x10004024 0x801f 0x04 0x1000402c 0x1f 0x10 0x10004030 0x801f 0x04 0x10004038 0xffffffff 0x1010101 0x1000403c 0xffff 0x101 0x10004040 0x01 0x01 0x10004044 0xffffffff 0x1010101 0x10004048 0x01 0x01 0x1000404c 0x801f 0x04>;
			tunable-hi_dn_merge_fabric = <0xfc004 0x07 0x04 0xfc008 0x8007 0x01 0xfc010 0x07 0x04 0xfc014 0x8007 0x01 0xfc01c 0x07 0x04 0xfc020 0x8007 0x01 0xfc028 0x07 0x04 0xfc02c 0x8007 0x01 0xfc034 0x07 0x04 0xfc038 0x8007 0x01 0xfc040 0x07 0x04 0xfc044 0x8007 0x01 0xfc04c 0x07 0x04 0xfc050 0x8007 0x01 0xfc058 0x07 0x04 0xfc05c 0x8007 0x01 0xfc064 0x07 0x04 0xfc068 0x8007 0x01 0xfc070 0x07 0x04 0xfc074 0x8007 0x01 0xfc07c 0x07 0x04 0xfc080 0x8007 0x01 0xfc088 0x07 0x04 0xfc08c 0x8007 0x01 0xfc094 0x07 0x04 0xfc098 0x8007 0x01 0xfc0a0 0x8007 0x01>;
			tunable-hi_up_merge_fabric = <0xf8004 0x1f 0x10 0xf8008 0x801f 0x04 0xf8010 0x3f 0x30 0xf8014 0x801f 0x04 0xf801c 0x1f 0x10 0xf8020 0x801f 0x04 0xf8028 0x7f 0x60 0xf802c 0x801f 0x04 0xf8034 0x8007 0x01>;
			tunable-hi_up_tx_desc_fabric = <0xf0004 0x0f 0x08 0xf0008 0x801f 0x04 0xf0010 0x0f 0x08 0xf0014 0x801f 0x04 0xf001c 0x0f 0x08 0xf0020 0x801f 0x04 0xf0028 0x0f 0x08 0xf002c 0x801f 0x04 0xf0034 0x0f 0x08 0xf0038 0x801f 0x04 0xf0040 0x0f 0x08 0xf0044 0x801f 0x04 0xf004c 0x0f 0x08 0xf0050 0x801f 0x04 0xf0058 0x0f 0x08 0xf005c 0x801f 0x04 0xf0064 0x0f 0x08 0xf0068 0x801f 0x04 0xf0070 0x0f 0x08 0xf0074 0x801f 0x04 0xf007c 0x0f 0x08 0xf0080 0x801f 0x04 0xf0088 0x0f 0x08 0xf008c 0x801f 0x04 0xf0094 0x8007 0x01>;
			tunable-hi_up_tx_data_fabric = <0xec004 0x3f 0x30 0xec008 0x801f 0x04 0xec010 0x3f 0x30 0xec014 0x801f 0x04 0xec01c 0x3f 0x30 0xec020 0x801f 0x04 0xec028 0x3f 0x30 0xec02c 0x801f 0x04 0xec034 0x3f 0x30 0xec038 0x801f 0x04 0xec040 0x3f 0x30 0xec044 0x801f 0x04 0xec04c 0x3f 0x30 0xec050 0x801f 0x04 0xec058 0x3f 0x30 0xec05c 0x801f 0x04 0xec064 0x3f 0x30 0xec068 0x801f 0x04 0xec070 0x3f 0x30 0xec074 0x801f 0x04 0xec07c 0x3f 0x30 0xec080 0x801f 0x04 0xec088 0x3f 0x30 0xec08c 0x801f 0x04 0xec094 0xffffffff 0x1010101 0xec098 0xffffffff 0x1010101 0xec09c 0xffffffff 0x1010101 0xec0a0 0xffffffff 0x1010101 0xec0a4 0xffffffff 0x1010101 0xec0a8 0xffffffff 0x1010101 0xec0ac 0x01 0x01 0xec0b0 0x8007 0x01>;
			tunable-hi_up_rx_desc_fabric = <0xe8004 0x0f 0x08 0xe8008 0x801f 0x04 0xe8010 0x0f 0x08 0xe8014 0x801f 0x04 0xe801c 0x0f 0x08 0xe8020 0x801f 0x04 0xe8028 0x0f 0x08 0xe802c 0x801f 0x04 0xe8034 0x0f 0x08 0xe8038 0x801f 0x04 0xe8040 0x0f 0x08 0xe8044 0x801f 0x04 0xe804c 0x0f 0x08 0xe8050 0x801f 0x04 0xe8058 0x0f 0x08 0xe805c 0x801f 0x04 0xe8064 0x0f 0x08 0xe8068 0x801f 0x04 0xe8070 0x0f 0x08 0xe8074 0x801f 0x04 0xe807c 0x0f 0x08 0xe8080 0x801f 0x04 0xe8088 0x0f 0x08 0xe808c 0x801f 0x04 0xe8094 0x8007 0x01>;
			tunable-hi_up_wr_fabric = <0xf4004 0x1f 0x10 0xf4008 0x801f 0x04 0xf4010 0x1f 0x10 0xf4014 0x801f 0x04 0xf401c 0x1f 0x10 0xf4020 0x801f 0x04 0xf4028 0x1f 0x10 0xf402c 0x801f 0x04 0xf4034 0x1f 0x10 0xf4038 0x801f 0x04 0xf4040 0x1f 0x10 0xf4044 0x801f 0x04 0xf404c 0x1f 0x10 0xf4050 0x801f 0x04 0xf4058 0x1f 0x10 0xf405c 0x801f 0x04 0xf4064 0x1f 0x10 0xf4068 0x801f 0x04 0xf4070 0x1f 0x10 0xf4074 0x801f 0x04 0xf407c 0x1f 0x10 0xf4080 0x801f 0x04 0xf4088 0x1f 0x10 0xf408c 0x801f 0x04 0xf4094 0x1f 0x10 0xf4098 0x801f 0x04 0xf40a0 0xffffffff 0x1010101 0xf40a4 0xffffffff 0x1010101 0xf40a8 0xffffffff 0x1010101 0xf40ac 0xffffffff 0x1010101 0xf40b0 0xffffffff 0x1010101 0xf40b4 0xffffffff 0x1010101 0xf40b8 0xffff 0x101 0xf40bc 0x01 0x01 0xf40c0 0x8007 0x01>;
			tunable-lbw_fabric = <0x10008004 0x70007 0x40004 0x10008008 0x801f 0x04 0x10008010 0x70007 0x40004 0x10008018 0x801f 0x04 0x10008020 0x70007 0x40004 0x10008028 0x801f 0x04 0x10008030 0x801f 0x04 0x10008038 0x801f 0x04 0x10008040 0x801f 0x04 0x10008048 0x801f 0x04 0x10008050 0x801f 0x04 0x10008058 0x801f 0x04 0x10008060 0x801f 0x04>;
			tunable-pcie_adapter_regs = <0x10385008 0x06 0x06>;
			tunable-top = <0x10000000 0xfff0 0x3010 0x1000002c 0x04 0x00>;
			thunderbolt-drom = <0xb5019718 0x75866001 0x533bb8 0xe9013d00 0x1000f00 0x1000881 0x81028100 0x882 0x91018100 0x383 0x20028405 0x85090100 0x5860901 0x2870d 0x1417070 0x6c652049 0x6e632e00 0x602694f 0x53000000>;
		};

		pciec1_dart@521008000 {
			compatible = "apple,dart-m1-64";
			clocks = <0x2a>;
			reg = <0x05 0x21008000 0x00 0x4000>;
			interrupts = <0x00 0x353 0x04>;
			pcie-dart;
			aperture = <0x00 0x80000000 0x00 0xfff00000>;
			page-bits = <0x0e>;
			sid-mask = <0xffffffff 0xffffffff>;
			#iommu-cells = <0x01>;
			phandle = <0x2b>;
		};

		pciec1@530000000 {
			compatible = "apple,pciec-m1";
			reg = <0x05 0x30000000 0x00 0x4000000 0x05 0x20000000 0x00 0x100000 0x05 0x20200000 0x00 0x100000 0x05 0x21000000 0x00 0x20000>;
			interrupt-parent = <0x01>;
			interrupts = <0x00 0x352 0x04 0x00 0x332 0x01 0x00 0x333 0x01 0x00 0x334 0x01 0x00 0x335 0x01 0x00 0x336 0x01 0x00 0x337 0x01 0x00 0x338 0x01 0x00 0x339 0x01 0x00 0x33a 0x01 0x00 0x33b 0x01 0x00 0x33c 0x01 0x00 0x33d 0x01 0x00 0x33e 0x01 0x00 0x33f 0x01 0x00 0x340 0x01 0x00 0x341 0x01 0x00 0x342 0x01 0x00 0x343 0x01 0x00 0x344 0x01 0x00 0x345 0x01 0x00 0x346 0x01 0x00 0x347 0x01 0x00 0x348 0x01 0x00 0x349 0x01 0x00 0x34a 0x01 0x00 0x34b 0x01 0x00 0x34c 0x01 0x00 0x34d 0x01 0x00 0x34e 0x01 0x00 0x34f 0x01 0x00 0x350 0x01 0x00 0x351 0x01>;
			clocks = <0x2a 0x22 0x17>;
			clock-names = "core\0aux\0ref";
			#address-cells = <0x03>;
			#size-cells = <0x02>;
			#interrupt-cells = <0x01>;
			device_type = "pci";
			msi-controller;
			msi-parent = <0x29>;
			msi-doorbell = <0x00 0xfffff000>;
			ranges = <0x43000000 0x05 0x80000000 0x05 0x80000000 0x00 0x80000000 0x2000000 0x00 0x100000 0x06 0x100000 0x00 0x3ff00000 0x42000000 0x00 0x40000000 0x06 0x40000000 0x00 0x40000000>;
			bus-range = <0x00 0x3f>;
			iommu-map = <0x00 0x2b 0x8000 0x100 0x100 0x2b 0x100 0x7e00>;
			iommu-map-mask = <0xff00>;
			external-facing;
			interrupt-map = <0x00 0x00 0x00 0x01 0x2c 0x01 0x00 0x00 0x00 0x02 0x2c 0x02 0x00 0x00 0x00 0x03 0x2c 0x03 0x00 0x00 0x00 0x04 0x2c 0x04>;
			interrupt-map-mask = <0x00 0x00 0x00 0x07>;
			phandle = <0x29>;
			tunable-debug = <0x20001000 0x01 0x00>;
			tunable-fabric = <0x10004004 0x1f001f 0x180018 0x10004008 0x01 0x01 0x1000400c 0x01 0x01 0x10004010 0x801f 0x04 0x10004018 0x3ff 0x280 0x10004044 0x01 0x01 0x10004094 0x801f 0x04 0x1000409c 0x801f 0x04 0x10004020 0x801f 0x04 0x10004028 0x3f 0x20 0x1000402c 0x801f 0x04 0x10004034 0x3f 0x20 0x10004038 0x801f 0x04 0x10004040 0x10001 0x10001 0x10004048 0x01 0x01 0x1000404c 0x801f 0x04 0x10004054 0x7f007f 0x4b004b 0x10004058 0x801f 0x04 0x10004060 0x801f 0x04 0x10004068 0x01 0x01 0x1000406c 0x801f 0x04 0x10004074 0x01 0x01 0x10004078 0x801f 0x04 0x10004084 0x801f 0x04 0x1000408c 0x01 0x01 0x10004090 0x01 0x01 0x100040a4 0x801f 0x04>;
			tunable-oe-fabric = <0x10008004 0x70007 0x40004 0x10008008 0x01 0x01 0x1000800c 0x01 0x01 0x10008010 0x801f 0x04 0x10008018 0x7f007f 0x450045 0x1000801c 0x801f 0x04 0x10008024 0x801f 0x04 0x1000802c 0x01 0x01 0x10008030 0x01 0x01 0x10008034 0x801f 0x04>;
			tunable-rc = <0x718 0x7c000 0x00 0x8bc 0x01 0x00 0x78 0x7000 0x00 0x814 0xffffffff 0xf060>;
			tunable-port0-config = <0x30000140 0x01 0x01>;

			legacy-interrupt-controller {
				interrupt-controller;
				#address-cells = <0x00>;
				#interrupt-cells = <0x01>;
				phandle = <0x2c>;
			};
		};

		usb_dart1@502f00000 {
			compatible = "apple,dart-m1";
			clocks = <0x1f>;
			reg = <0x05 0x2f00000 0x00 0x80000 0x05 0x2f80000 0x00 0x4000>;
			interrupts = <0x00 0x35d 0x04>;
			page-bits = <0x0e>;
			sid-mask = <0x0b>;
			sid-remap = <0x00 0x01>;
			#iommu-cells = <0x01>;
			phandle = <0x2d>;
		};

		usb_drd1@502280000 {
			compatible = "apple,dwc3-m1";
			clock-names = "usbclk\0utmiclk";
			reg = <0x05 0x00 0x00 0x1000000 0x05 0x2000000 0x00 0x1000000>;
			reg-names = "atcphy\0usbcore";
			#address-cells = <0x02>;
			#size-cells = <0x02>;
			ranges;
			tunable-ATC0AXI2AF = <0x00 0x03 0x00 0x30 0xffffffff 0xffff 0x34 0xffffffff 0xffff 0x400 0x400103ff 0x40010001 0x600 0x1ffffff 0x1ffffff 0x738 0x1ff01ff 0x400040 0x798 0x1ff01ff 0x600020 0x800 0x100 0x100 0x900 0x03 0x00 0x920 0x03 0x00>;
			tunable = <0x1028c164 0x02 0x00 0x1028c200 0x2000000 0x2000000 0x10200018 0xff 0x1b 0x10a84020 0xf00 0x700 0x1008001c 0x3f003f 0x200020 0x10080020 0x801f 0x04 0x10080028 0x01 0x01 0x1008002c 0x01 0x01 0x10080030 0x801f 0x04>;

			dwc3@502280000 {
				compatible = "snps,dwc3";
				reg = <0x05 0x2280000 0x00 0x100000>;
				interrupts = <0 0x359 0x4>;
				iommus = <0x2d 0x01>;
				#address-cells = <0x01>;
				#size-cells = <0x00>;
				dr_mode = "host";
				phys = <0x27 0x27>;
				phy-names = "usb2-phy\0usb3-phy";

				port@0 {
					reg = <0x00>;

					endpoint {
						remote-endpoint = <0x2e>;
						phandle = <0x0d>;
					};
				};

				port@1 {
					reg = <0x01>;

					endpoint {
						remote-endpoint = <0x2f>;
						phandle = <0x21>;
					};
				};
			};
		};

		pcie_refclk@23b7001a0 {
			compatible = "apple,pmgr-clk-gate";
			#clock-cells = <0x00>;
			reg = <0x02 0x3b7001a0 0x00 0x08>;
			clocks = <0x17>;
			clock-output-names = "pcie_refclk";
			phandle = <0x35>;
		};

		imx_clk@23b7001b8 {
			compatible = "apple,pmgr-clk-gate";
			#clock-cells = <0x00>;
			reg = <0x02 0x3b7001b8 0x00 0x08>;
			clocks = <0x17>;
			clock-output-names = "imx_clk";
			phandle = <0x30>;
		};

		pcie_clk@23b700348 {
			compatible = "apple,pmgr-clk-gate";
			#clock-cells = <0x00>;
			reg = <0x02 0x3b700348 0x00 0x08>;
			clocks = <0x30>;
			clock-output-names = "pcie_clk";
			phandle = <0x31>;
		};

		pcie_gp_clk@23b7003e8 {
			compatible = "apple,pmgr-clk-gate";
			#clock-cells = <0x00>;
			reg = <0x02 0x3b7003e8 0x00 0x08>;
			clocks = <0x31>;
			clock-output-names = "pcie_gp_clk";
			phandle = <0x32>;
		};

		pcie_dart0@681008000 {
			compatible = "apple,dart-m1";
			clocks = <0x32>;
			reg = <0x06 0x81008000 0x00 0x4000>;
			interrupts = <0x00 0x2b8 0x04>;
			pcie-dart;
			page-bits = <0x0e>;
			sid-mask = <0xffff>;
			#iommu-cells = <0x01>;
			phandle = <0x39>;
		};

		pcie_dart1@682008000 {
			compatible = "apple,dart-m1";
			clocks = <0x32>;
			reg = <0x06 0x82008000 0x00 0x4000>;
			interrupts = <0x00 0x2bb 0x04>;
			pcie-dart;
			page-bits = <0x0e>;
			sid-mask = <0xffff>;
			#iommu-cells = <0x01>;
			phandle = <0x3a>;
		};

		pcie_dart2@683008000 {
			compatible = "apple,dart-m1";
			clocks = <0x32>;
			reg = <0x06 0x83008000 0x00 0x4000>;
			interrupts = <0x00 0x2be 0x04>;
			pcie-dart;
			page-bits = <0x0e>;
			sid-mask = <0xffff>;
			#iommu-cells = <0x01>;
			phandle = <0x3b>;
		};

		smc_mbox@23e408800 {
			compatible = "apple,iop-mailbox-m1";
			reg = <0x02 0x3e400000 0x00 0x20000>;
			interrupts = <0x00 0x190 0x04 0x00 0x193 0x04>;
			#mbox-cells = <0x01>;
			endpoints = <0x20>;
			phandle = <0x33>;
		};

		aop_mbox@24a400000 {
			compatible = "apple,iop-mailbox-m1";
			reg = <0x02 0x4a400000 0x00 0x20000>;
			interrupts = <0x00 285 0x04 0x00 288 0x04>;
			#mbox-cells = <0x01>;
			endpoints = <0x20>;
			debug-trace;
		};

		pmp_mbox@23bc00000 {
			compatible = "apple,iop-mailbox-m1";
			reg = <0x02 0x3bc00000 0x00 0x20000>;
			interrupts = <0x00 511 0x04 0x00 514 0x04>;
			#mbox-cells = <0x01>;
			endpoints = <0x20>;
			debug-trace;
		};

		sio_mbox@236400000 {
			compatible = "apple,iop-mailbox-m1";
			reg = <0x02 0x36400000 0x00 0x20000>;
			interrupts = <0x00 640 0x04 0x00 643 0x04>;
			#mbox-cells = <0x01>;
			endpoints = <0x20>;
			debug-trace;
		};

		sep_mbox@242400000 {
			compatible = "apple,iop-mailbox-m1";
			reg = <0x02 0x42400000 0x00 0x20000>;
			interrupts = <0x00 253 0x04 0x00 256 0x04>;
			#mbox-cells = <0x01>;
			debug-trace;
			endpoints = <0x20>;
		};

		dcp_mbox@231c00000 {
			compatible = "apple,iop-mailbox-m1";
			reg = <0x02 0x31c00000 0x00 0x20000>;
			interrupts = <0x00 427 0x04 0x00 430 0x04>;
			#mbox-cells = <0x01>;
			debug-trace;
			endpoints = <0x20>;
		};

		gfx_asc_mbox@206400000 {
			compatible = "apple,iop-mailbox-m1";
			reg = <0x02 0x06400000 0x00 0x20000>;
			interrupts = <0x00 575 0x04 0x00 578 0x04>;
			#mbox-cells = <0x01>;
			debug-trace;
			endpoints = <0x20>;
		};

		smc@23e050000 {
			compatible = "apple,smc-m1";
			reg = <0x02 0x3e050000 0x00 0x4000>;
			mboxes = <0x33 0x20>;
			gpio-controller;
			#gpio-cells = <0x02>;
			gpio-9 = <0x10000>;
			gpio-13 = <0x800000>;
			gpio-15 = <0x00>;
			gpio-20 = <0x00>;
			nvmem = <0x34>;
			nvmem-poweroff = <0x01 0xff 0x00 0x03 0xff 0x00 0x0f 0x2f 0x08>;
			phandle = <0x37>;
		};

		pcie@690000000 {
			compatible = "apple,pcie-m1";
			reg = <0x06 0x90000000 0x00 0x1000000 0x06 0x80000000 0x00 0x100000 0x06 0x8c000000 0x00 0x100000 0x06 0x81000000 0x00 0x20000 0x06 0x82000000 0x00 0x20000 0x06 0x83000000 0x00 0x20000>;
			interrupt-parent = <0x01>;
			interrupts = <0x00 0x2b7 0x04 0x00 0x2ba 0x04 0x00 0x2bd 0x04 0x00 0x2c0 0x01 0x00 0x2c1 0x01 0x00 0x2c2 0x01 0x00 0x2c3 0x01 0x00 0x2c4 0x01 0x00 0x2c5 0x01 0x00 0x2c6 0x01 0x00 0x2c7 0x01 0x00 0x2c8 0x01 0x00 0x2c9 0x01 0x00 0x2ca 0x01 0x00 0x2cb 0x01 0x00 0x2cc 0x01 0x00 0x2cd 0x01 0x00 0x2ce 0x01 0x00 0x2cf 0x01 0x00 0x2d0 0x01 0x00 0x2d1 0x01 0x00 0x2d2 0x01 0x00 0x2d3 0x01 0x00 0x2d4 0x01 0x00 0x2d5 0x01 0x00 0x2d6 0x01 0x00 0x2d7 0x01 0x00 0x2d8 0x01 0x00 0x2d9 0x01 0x00 0x2da 0x01 0x00 0x2db 0x01 0x00 0x2dc 0x01 0x00 0x2dd 0x01 0x00 0x2de 0x01 0x00 0x2df 0x01>;
			clocks = <0x32 0x31 0x35>;
			clock-names = "core\0aux\0ref";
			pinctrl-0 = <0x36>;
			pinctrl-names = "default";
			perst-gpios = <0x0c 0x98 0x00 0x0c 0x99 0x00 0x0c 0x21 0x00>;
			clkreq-gpios = <0x0c 0x96 0x00 0x0c 0x97 0x00 0x0c 0x20 0x00>;
			devpwr-gpios = <0x37 0x0d 0x00>;
			devpwr-on-0 = <0x00 0x01>;
			devpwr-on-1;
			devpwr-on-2;
			#address-cells = <0x03>;
			#size-cells = <0x02>;
			#interrupt-cells = <0x01>;
			device_type = "pci";
			msi-controller;
			msi-parent = <0x38>;
			msi-doorbell = <0x00 0xfffff000>;
			ranges = <0x43000000 0x06 0xa0000000 0x06 0xa0000000 0x00 0x20000000 0x2000000 0x00 0xc0000000 0x06 0xc0000000 0x00 0x40000000>;
			bus-range = <0x00 0x0f>;
			iommu-map = <0x00 0x39 0x8000 0x100 0x100 0x39 0x100 0x100 0x200 0x3a 0x200 0x100 0x300 0x3b 0x300 0x100>;
			iommu-map-mask = <0xff00>;
			refclk-always-on-2;
			max-speed-2 = <0x01>;
			phandle = <0x38>;
			tunable-axi2af = <0x20000000 0x03 0x00 0x20000038 0xffffffff 0xffff 0x2000003c 0xffffffff 0xffff 0x20000400 0x400103ff 0x40010001 0x20000600 0x1ffffff 0x1ffffff 0x20000738 0x1ff01ff 0x200020 0x20000798 0x1ff01ff 0x600010 0x20000800 0x100 0x100>;
			tunable-common = <0x1000002c 0xff 0x01 0x10000054 0xffffffff 0x140>;
			tunable-phy-ip-auspma = <0x100ca10c 0x3fffffff 0x3fffffff 0x100cd024 0xee 0x2c 0x100cb028 0x600 0x600 0x100cb02c 0x70 0x50 0x100cb038 0x3800000 0x3000000 0x100cb03c 0x7000000 0x7000000 0x100cb044 0xf0000000 0x70000000 0x100cb01c 0x7fc0fff 0x1c00c21 0x100cc008 0xfc00 0x3800 0x100cc030 0x3fc0 0x2a00 0x100cc080 0xf80000 0x180000 0x100cc08c 0xffffff0 0x2222220 0x100c9014 0x40000 0x40000 0x100c902c 0x70000000 0x60000000 0x100c9040 0x70000 0x40000 0x100c9068 0x38 0x18 0x100c9074 0x3f 0x3e 0x100c90ac 0x1f8000 0x40000 0x100c9104 0xffff 0x202 0x100c9108 0x03 0x00 0x100c9110 0xffffff0 0x2222220 0x100c9000 0x40000000 0x00 0x100c9030 0xeeffff03 0xff0001 0x100cb028 0x600 0x600 0x100cb02c 0x70 0x50 0x100cb038 0x3800000 0x3000000 0x100cb03c 0x7000000 0x7000000 0x100cb044 0xf0000000 0x70000000 0x100cb01c 0x7fc0fff 0x1c00c21 0x100c9014 0x40000 0x40000 0x100c902c 0x70000000 0x60000000 0x100c9040 0x70000 0x40000 0x100c9068 0x38 0x18 0x100c9074 0x3f 0x3e 0x100c90ac 0x1f8000 0x40000 0x100c9104 0xffff 0x202 0x100c9108 0x03 0x00 0x100c9110 0xffffff0 0x2222220 0x100c9000 0x40000000 0x00 0x100c9030 0xeeffff03 0xff0001 0x100ca10c 0x3fffffff 0x3fffffff 0x100d210c 0x3fffffff 0x3fffffff 0x100d5024 0xee 0x2c 0x100d3028 0x600 0x600 0x100d302c 0x70 0x50 0x100d3038 0x3800000 0x3000000 0x100d303c 0x7000000 0x7000000 0x100d3044 0xf0000000 0x70000000 0x100d301c 0x7fc0fff 0x1c00c21 0x100d4008 0xfc00 0x3800 0x100d4030 0x3fc0 0x2a00 0x100d4080 0xf80000 0x180000 0x100d408c 0xffffff0 0x2222220 0x100d1014 0x40000 0x40000 0x100d102c 0x70000000 0x60000000 0x100d1040 0x70000 0x40000 0x100d1068 0x38 0x18 0x100d1074 0x3f 0x3e 0x100d10ac 0x1f8000 0x40000 0x100d1104 0xffff 0x202 0x100d1108 0x03 0x00 0x100d1110 0xffffff0 0x2222220 0x100d1000 0x40000000 0x00 0x100d1030 0xeeffff03 0xff0001 0x100d3028 0x600 0x600 0x100d302c 0x70 0x50 0x100d3038 0x3800000 0x3000000 0x100d303c 0x7000000 0x7000000 0x100d3044 0xf0000000 0x70000000 0x100d301c 0x7fc0fff 0x1c00c21 0x100d1014 0x40000 0x40000 0x100d102c 0x70000000 0x60000000 0x100d1040 0x70000 0x40000 0x100d1068 0x38 0x18 0x100d1074 0x3f 0x3e 0x100d10ac 0x1f8000 0x40000 0x100d1104 0xffff 0x202 0x100d1108 0x03 0x00 0x100d1110 0xffffff0 0x2222220 0x100d1000 0x40000000 0x00 0x100d1030 0xeeffff03 0xff0001 0x100d210c 0x3fffffff 0x3fffffff 0x100da10c 0x3fffffff 0x3fffffff 0x100dd024 0xee 0x2c 0x100db028 0x600 0x600 0x100db02c 0x70 0x50 0x100db038 0x3800000 0x3000000 0x100db03c 0x7000000 0x7000000 0x100db044 0xf0000000 0x70000000 0x100db01c 0x7fc0fff 0x1c00c21 0x100dc008 0xfc00 0x3800 0x100dc030 0x3fc0 0x2a00 0x100dc080 0xf80000 0x180000 0x100dc08c 0xffffff0 0x2222220 0x100d9014 0x40000 0x40000 0x100d902c 0x70000000 0x60000000 0x100d9040 0x70000 0x40000 0x100d9068 0x38 0x18 0x100d9074 0x3f 0x3e 0x100d90ac 0x1f8000 0x40000 0x100d9104 0xffff 0x202 0x100d9108 0x03 0x00 0x100d9110 0xffffff0 0x2222220 0x100d9000 0x40000000 0x00 0x100d9030 0xeeffff03 0xff0001 0x100db028 0x600 0x600 0x100db02c 0x70 0x50 0x100db038 0x3800000 0x3000000 0x100db03c 0x7000000 0x7000000 0x100db044 0xf0000000 0x70000000 0x100db01c 0x7fc0fff 0x1c00c21 0x100d9014 0x40000 0x40000 0x100d902c 0x70000000 0x60000000 0x100d9040 0x70000 0x40000 0x100d9068 0x38 0x18 0x100d9074 0x3f 0x3e 0x100d90ac 0x1f8000 0x40000 0x100d9104 0xffff 0x202 0x100d9108 0x03 0x00 0x100d9110 0xffffff0 0x2222220 0x100d9000 0x40000000 0x00 0x100d9030 0xeeffff03 0xff0001 0x100da10c 0x3fffffff 0x3fffffff>;
			tunable-phy-ip-pll = <0x100c002c 0x1fe00 0x9000 0x100c1200 0x3fc00 0x3c000 0x100c402c 0x3c0000 0x40000 0x100c5080 0x3ffc0000 0x298c0000 0x100c5088 0xf0000 0x60000 0x100c508c 0x3ffc0000 0x298c0000 0x100c5094 0xf0000 0x60000 0x100c50a0 0xf0000 0x50000 0x100c50ac 0xf0000 0x50000 0x100c50b8 0xf0000 0x50000 0x100c5200 0x06 0x06 0x100c5220 0x07 0x00 0x100c5224 0x3fc00000 0x18000000 0x100c522c 0x900 0x900 0x100c5230 0x3e0000 0x200000 0x100c5278 0x8000000 0x00 0x100c52a4 0x01 0x01 0x100c52bc 0xffffff 0x78078 0x100c608c 0x3c3c0000 0x200c0000 0x100c6200 0x06 0x06 0x100c6214 0x01 0x00 0x100c621c 0x7000 0x00 0x100c6220 0x07 0x01 0x100c6224 0x03 0x01 0x100c6228 0x10 0x10 0x100c6230 0x3e0000 0x200000 0x100c62bc 0xffffff 0x78078>;
			tunable-phy = <0x10080008 0x01 0x01 0x10084004 0x77 0x35 0x10088004 0x77 0x35 0x1008c004 0x77 0x35>;
			tunable-port0-config = <0x30000140 0x01 0x01 0x30000144 0xffffff 0x253770 0x30000800 0xff0000 0x100000>;
			tunable-port0-gen3-shadow = <0x154 0xf0f 0x404 0x890 0x3000000 0x00 0x8a8 0xffff00 0x1000>;
			tunable-port0-gen4-shadow = <0x178 0xff 0x44 0x890 0x3000000 0x1000000 0x8a8 0xffff00 0x1000>;
			tunable-port0 = <0x194 0xfbff00 0x00 0x2a4 0x80000000 0x00 0x890 0x01 0x00 0xb80 0x3f7f3f3f 0x1d1f3220 0xb84 0x3f3f 0x3f3f 0x78 0x7000 0x00>;
			tunable-fuse = <0x100c6238 0x7f 0x20 0x100c6220 0x1c000 0x14000 0x100c62a4 0x60000 0x40000 0x100c522c 0x600 0x600 0x100c522c 0x7000 0x4000 0x100c5220 0x1c000 0x8000 0x100c52a4 0x60000 0x40000 0x100c522c 0x1f0000 0x100000 0x100c5278 0x700000 0x00 0x100c5018 0x04 0x00 0x100c1204 0x7c 0x3c>;
		};

		spi_p_clk@23b700218 {
			compatible = "apple,pmgr-clk-gate";
			#clock-cells = <0x00>;
			reg = <0x02 0x3b700218 0x00 0x08>;
			clocks = <0x09>;
			clock-output-names = "spi_p_clk";
			phandle = <0x3c>;
		};

		spi1_clk@23b700248 {
			compatible = "apple,pmgr-clk-gate";
			#clock-cells = <0x00>;
			reg = <0x02 0x3b700248 0x00 0x08>;
			clocks = <0x3c>;
			clock-output-names = "spi1_clk";
			phandle = <0x3d>;
		};

		spi@235104000 {
			compatible = "apple,spi-mc-m1";
			reg = <0x02 0x35104000 0x00 0x4000>;
			interrupts = <0x00 0x267 0x04>;
			clocks = <0x3d>;
			cs-gpios = <0x0c 0x2d 0x00>;
			#address-cells = <0x01>;
			#size-cells = <0x00>;

			flash@0 {
				compatible = "jedec,spi-nor";
				reg = <0x00>;
				spi-max-frequency = <0x2dc6c0>;
			};
		};

		spi3_clk@23b700258 {
			compatible = "apple,pmgr-clk-gate";
			#clock-cells = <0x00>;
			reg = <0x02 0x3b700258 0x00 0x08>;
			clocks = <0x3c>;
			clock-output-names = "spi3_clk";
			phandle = <0x3e>;
		};

		spi@23510c000 {
			compatible = "apple,spi-mc-m1";
			reg = <0x02 0x3510c000 0x00 0x4000>;
			interrupts = <0x00 0x269 0x04>;
			clocks = <0x3e>;
			cs-gpios = <0x0c 0x31 0x00>;
			#address-cells = <0x01>;
			#size-cells = <0x00>;

			keyboard@0 {
				compatible = "input,applespi-kbd-v1";
				reg = <0x00>;
				spi-max-frequency = <0x1e8480>;
				spien-gpios = <0x0c 0xc3 0x00>;
				irq-gpios = <0x3f 0x0d 0x00>;
				interrupt-parent = <0x3f>;
				interrupts = <0x0d 0x08>;
			};
		};

		spi@235110000 {
			compatible = "apple,spi-mc-m1";
			reg = <0x02 0x35110000 0x00 0x4000>;
			interrupts = <0x00 0x26a 0x04>;
			clocks = <0x3e>;
			cs-gpios = <0x0c 0x18 0x00>;
			#address-cells = <0x01>;
			#size-cells = <0x00>;
		};

		spi@235100000 {
			compatible = "apple,spi-mc-m1";
			reg = <0x02 0x35100000 0x00 0x4000>;
			interrupts = <0x00 614 0x04>;
			clocks = <0x3e>;
			cs-gpios = <0x0c 0x00 0x00>;
			#address-cells = <0x01>;
			#size-cells = <0x00>;

			spidev@0 {
				compatible = "spidev";
				reg = <0x00>;
				interrupts = <0x00 0xc2 0x02>;
				spien-gpios = <0x0c 0x8b 0x00>;
			};

/*
			keyboard2@0 {
				compatible = "input,applespi-kbd-v1";
				reg = <0x00>;
				spi-max-frequency = <120000>;
				irq-gpios = <0x0c 0xc2 0x00>;
				interrupt-parent = <0x0c>;
				interrupts = <0x00 0xc2 0x02>;
				spien-gpios = <0x0c 0x8b 0x00>;
			};
			*/
		};

		ans_clk@23b7003f0 {
			compatible = "apple,pmgr-clk-gate";
			#clock-cells = <0x00>;
			reg = <0x02 0x3b7003f0 0x00 0x08>;
			clocks = <0x31>;
			clock-output-names = "ans_clk";
			phandle = <0x40>;
		};

		pcie_st_clk@23b700418 {
			compatible = "apple,pmgr-clk-gate";
			#clock-cells = <0x00>;
			reg = <0x02 0x3b700418 0x00 0x08>;
			clocks = <0x40>;
			clock-output-names = "pcie_st_clk";
			phandle = <0x41>;
		};

		ans_mbox@277400000 {
			compatible = "apple,iop-mailbox-m1";
			reg = <0x02 0x77400000 0x00 0x20000>;
			interrupts = <0x00 0x247 0x04 0x00 0x24a 0x04>;
			clocks = <0x41>;
			#mbox-cells = <0x01>;
			endpoints = <0x20>;
			wait-init;
			phandle = <0x42>;
		};

		ans@27bcc0000 {
			compatible = "apple,nvme-m1";
			reg = <0x02 0x7bcc0000 0x00 0x40000 0x02 0x7bc50000 0x00 0x4000>;
			interrupts = <0x00 0x24e 0x04>;
			clocks = <0x41>;
			mboxes = <0x42 0x20>;
			#address-cells = <0x03>;
			#size-cells = <0x02>;
			#interrupt-cells = <0x01>;
			device_type = "pci";
			msi-controller;
			msi-parent = <0x43>;
			ranges = <0x2000000 0x00 0x7bc00000 0x02 0x7bc00000 0x00 0x100000>;
			bus-range = <0x00 0x01>;
			phandle = <0x43>;
		};

		nub_spmi0_clk@23d280060 {
			compatible = "apple,pmgr-clk-gate";
			#clock-cells = <0x00>;
			reg = <0x02 0x3d280060 0x00 0x08>;
			clocks = <0x03>;
			clock-output-names = "nub_spmi0_clk";
			phandle = <0x44>;
		};

		spmi@23d0d8000 {
			compatible = "apple,spmi-m1";
			reg = <0x02 0x3d0d8000 0x00 0x2000>;
			interrupts = <0x00 0x157 0x04>;
			clocks = <0x44>;
			#address-cells = <0x02>;
			#size-cells = <0x00>;
			interrupt-controller;
			#interrupt-cells = <0x02>;
			phandle = <0x45>;

			pmu@f {
				compatible = "apple,spmi-pmu-sera\0apple,spmi-pmu";
				reg = <0x0f 0x00>;
				interrupt-parent = <0x45>;
				interrupts = <0x02 0x00>;

				rtc@d002 {
					compatible = "apple,spmi-rtc-v0";
					base = <0xd002 0x06 0xd100 0x06>;
				};

				sysctrl@9f00 {
					compatible = "apple,spmi-bbram-v0";
					base = <0x9f00 0x20>;
					phandle = <0x34>;
				};

				bbram@a000 {
					compatible = "apple,spmi-bbram-v0";
					base = <0xa000 0x1000>;
				};
			};
		};

		reboot@23d2b0000 {
			compatible = "apple,reboot-v0";
			reg = <0x02 0x3d2b0000 0x00 0x4000>;
		};

		fpwm0_clk@23b7001e0 {
			compatible = "apple,pmgr-clk-gate";
			#clock-cells = <0x00>;
			reg = <0x02 0x3b7001e0 0x00 0x08>;
			clocks = <0x03>;
			clock-output-names = "fpwm0_clk";
			phandle = <0x46>;
		};

		pwm@235044000 {
			compatible = "apple,fpwm-t8101";
			reg = <0x02 0x35044000 0x00 0x4000>;
			clocks = <0x46>;
			#pwm-cells = <0x02>;
			phandle = <0x47>;
		};

		wdt@23d2b0000 {
			compatible = "apple,wdt";
			reg = <0x2 0x3d2b0000 0x00 0x4000>;
		};
	};

	leds {
		compatible = "pwm-leds";

		kbd-backlight {
			label = "kbd_backlight";
			pwms = <0x47 0x00 0x3e8>;
			max-brightness = <0xff>;
		};
	};

	backlight {
		compatible = "gpio-backlight";
		gpios = <0x37 0x12 0x00>;
		default-on;
		status = "okay";
		phandle = <0x02>;
	};
};
